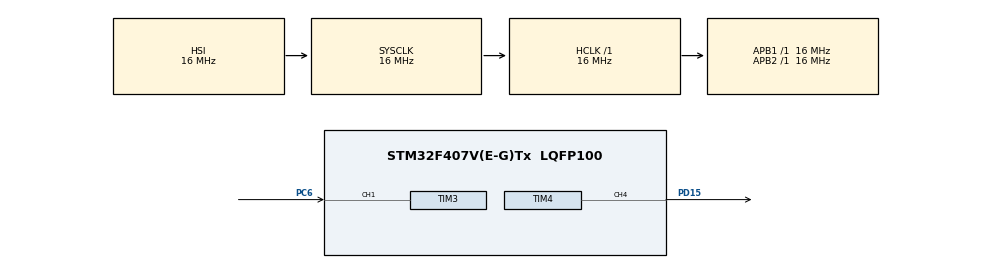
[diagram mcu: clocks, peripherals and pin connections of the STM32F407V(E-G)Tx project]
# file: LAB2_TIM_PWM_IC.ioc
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Dma.Request0=TIM3_CH1/TRIG
Dma.Request1=TIM3_CH2
Dma.TIM3_CH1/TRIG.0.Direction=DMA_PERIPH_TO_MEMORY
Dma.TIM3_CH1/TRIG.0.FIFOMode=DMA_FIFOMODE_DISABLE
Dma.TIM3_CH1/TRIG.0.Instance=DMA1_Stream4
Dma.TIM3_CH1/TRIG.0.MemDataAlignment=DMA_MDATAALIGN_HALFWORD
Dma.TIM3_CH1/TRIG.0.MemInc=DMA_MINC_ENABLE
Dma.TIM3_CH1/TRIG.0.Mode=DMA_CIRCULAR
Dma.TIM3_CH1/TRIG.0.PeriphDataAlignment=DMA_PDATAALIGN_HALFWORD
Dma.TIM3_CH1/TRIG.0.PeriphInc=DMA_PINC_DISABLE
Dma.TIM3_CH1/TRIG.0.Priority=DMA_PRIORITY_LOW
Dma.TIM3_CH2.1.Direction=DMA_PERIPH_TO_MEMORY
Dma.TIM3_CH2.1.FIFOMode=DMA_FIFOMODE_DISABLE
Dma.TIM3_CH2.1.Instance=DMA1_Stream5
Dma.TIM3_CH2.1.MemDataAlignment=DMA_MDATAALIGN_HALFWORD
Dma.TIM3_CH2.1.MemInc=DMA_MINC_ENABLE
Dma.TIM3_CH2.1.Mode=DMA_CIRCULAR
Dma.TIM3_CH2.1.PeriphDataAlignment=DMA_PDATAALIGN_HALFWORD
Dma.TIM3_CH2.1.PeriphInc=DMA_PINC_DISABLE
Dma.TIM3_CH2.1.Priority=DMA_PRIORITY_LOW
Mcu.Family=STM32F4
Mcu.Name=STM32F407V(E-G)Tx
Mcu.Package=LQFP100
NVIC.DMA1_Stream4_IRQn=true\:0\:0\:false\:false\:true\:false\:true\:true
NVIC.DMA1_Stream5_IRQn=true\:0\:0\:false\:false\:true\:false\:true\:true
NVIC.PriorityGroup=NVIC_PRIORITYGROUP_4
NVIC.TIM3_IRQn=true\:0\:0\:false\:false\:true\:true\:true\:true
PA13.Mode=Serial_Wire
PA13.Signal=SYS_JTMS-SWDIO
PA14.Mode=Serial_Wire
PA14.Signal=SYS_JTCK-SWCLK
PC6.Signal=S_TIM3_CH1
PD15.Signal=S_TIM4_CH4
ProjectManager.HeapSize=0x200
ProjectManager.StackSize=0x400
ProjectManager.TargetToolchain=MDK-ARM V5.32
RCC.AHBFreq_Value=16000000
RCC.APB1Freq_Value=16000000
RCC.APB2Freq_Value=16000000
RCC.CortexFreq_Value=16000000
RCC.HSE_VALUE=25000000
RCC.HSI_VALUE=16000000
RCC.LSE_VALUE=32768
RCC.SYSCLKFreq_VALUE=16000000
RCC.VCOOutputFreq_Value=192000000
SH.S_TIM3_CH1.0=TIM3_CH1,Input_Capture1_from_TI1
SH.S_TIM3_CH1.1=TIM3_CH1,TriggerSource_TI1FP1
SH.S_TIM4_CH4.0=TIM4_CH4,PWM Generation4 CH4
TIM3.Channel-Input_Capture1_from_TI1=TIM_CHANNEL_1
TIM3.Channel-Input_Capture2_from_TI1_63=TIM_CHANNEL_2
TIM3.ICPolarity_CH2=TIM_INPUTCHANNELPOLARITY_FALLING
TIM3.Prescaler=16-1
TIM3.TIM_MasterSlaveMode=TIM_MASTERSLAVEMODE_DISABLE
TIM4.Channel-PWM\ Generation4\ CH4=TIM_CHANNEL_4
TIM4.Period=2500-1
TIM4.Prescaler=16-1
TIM4.Pulse-PWM\ Generation4\ CH4=250
VP_TIM3_VS_ClockSourceINT.Mode=Internal
VP_TIM3_VS_ControllerModeReset.Mode=Reset Mode
VP_TIM3_VS_indirect_ch1.Mode=Input_Capture2_from_TI1_63
VP_TIM4_VS_ClockSourceINT.Mode=Internal
board=custom

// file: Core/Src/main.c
/* USER CODE BEGIN Header */
/**
  ******************************************************************************
  * @file           : main.c
  * @brief          : Main program body
  ******************************************************************************
  * @attention
  *
  * Copyright (c) 2023 STMicroelectronics.
  * All rights reserved.
  *
  * This software is licensed under terms that can be found in the LICENSE file
  * in the root directory of this software component.
  * If no LICENSE file comes with this software, it is provided AS-IS.
  *
  ******************************************************************************
  */
/* USER CODE END Header */
#include "main.h"
#include "dma.h"
#include "tim.h"
#include "gpio.h"

/* USER CODE BEGIN PV */
uint16_t t0 = 0;
uint16_t t1 = 0;
uint16_t t2 = 0;
uint16_t period = 0;
uint16_t pulse = 0;

#define BUFFER_SIZE 10
uint16_t buffer_ch1[BUFFER_SIZE] =  {0};
uint16_t buffer_ch2[BUFFER_SIZE] =  {0};
/* USER CODE END PV */

void SystemClock_Config(void);

int main(void)
{

  /* MCU Configuration--------------------------------------------------------*/

  /* Reset of all peripherals, Initializes the Flash interface and the Systick. */
  HAL_Init();

  /* Configure the system clock */
  SystemClock_Config();

  /* Initialize all configured peripherals */
  MX_GPIO_Init();
  MX_DMA_Init();
  MX_TIM3_Init();
  MX_TIM4_Init();
  /* USER CODE BEGIN 2 */
	HAL_TIM_Base_Start(&htim4);
	HAL_TIM_PWM_Start(&htim4, TIM_CHANNEL_4);

//	HAL_TIM_IC_Start_IT(&htim3, TIM_CHANNEL_1);
//	HAL_TIM_IC_Start_IT(&htim3, TIM_CHANNEL_2);
	HAL_TIM_IC_Start_DMA(&htim3, TIM_CHANNEL_1, (uint32_t *)buffer_ch1, BUFFER_SIZE);
	HAL_TIM_IC_Start_DMA(&htim3, TIM_CHANNEL_2, (uint32_t *)buffer_ch2, BUFFER_SIZE);
	HAL_TIM_Base_Start(&htim3);
  /* USER CODE END 2 */

  /* Infinite loop */
  /* USER CODE BEGIN WHILE */
  while (1)
  {
		uint32_t temp_period = 0;
		uint32_t temp_pulse = 0;
		for (uint8_t i = 0; i < BUFFER_SIZE; i++)
		{
			temp_period += buffer_ch1[i];
			temp_pulse += buffer_ch2[i];
		}
		period = temp_period / BUFFER_SIZE;
		pulse = temp_pulse / BUFFER_SIZE;
    /* USER CODE END WHILE */

  }
}

void SystemClock_Config(void)
{
  RCC_OscInitTypeDef RCC_OscInitStruct = {0};
  RCC_ClkInitTypeDef RCC_ClkInitStruct = {0};

  /** Configure the main internal regulator output voltage
  */
  __HAL_RCC_PWR_CLK_ENABLE();
  __HAL_PWR_VOLTAGESCALING_CONFIG(PWR_REGULATOR_VOLTAGE_SCALE1);

  /** Initializes the RCC Oscillators according to the specified parameters
  * in the RCC_OscInitTypeDef structure.
  */
  RCC_OscInitStruct.OscillatorType = RCC_OSCILLATORTYPE_HSI;
  RCC_OscInitStruct.HSIState = RCC_HSI_ON;
  RCC_OscInitStruct.HSICalibrationValue = RCC_HSICALIBRATION_DEFAULT;
  RCC_OscInitStruct.PLL.PLLState = RCC_PLL_NONE;
  if (HAL_RCC_OscConfig(&RCC_OscInitStruct) != HAL_OK)
  {
    Error_Handler();
  }

  /** Initializes the CPU, AHB and APB buses clocks
  */
  RCC_ClkInitStruct.ClockType = RCC_CLOCKTYPE_HCLK|RCC_CLOCKTYPE_SYSCLK
                              |RCC_CLOCKTYPE_PCLK1|RCC_CLOCKTYPE_PCLK2;
  RCC_ClkInitStruct.SYSCLKSource = RCC_SYSCLKSOURCE_HSI;
  RCC_ClkInitStruct.AHBCLKDivider = RCC_SYSCLK_DIV1;
  RCC_ClkInitStruct.APB1CLKDivider = RCC_HCLK_DIV1;
  RCC_ClkInitStruct.APB2CLKDivider = RCC_HCLK_DIV1;

  if (HAL_RCC_ClockConfig(&RCC_ClkInitStruct, FLASH_LATENCY_0) != HAL_OK)
  {
    Error_Handler();
  }
}

/* USER CODE BEGIN 4 */

void HAL_TIM_IC_CaptureCallback(TIM_HandleTypeDef *htim)
{
	if (htim->Channel == HAL_TIM_ACTIVE_CHANNEL_1)
	{
		t0 = t2;
		t2 = __HAL_TIM_GET_COMPARE(&htim3, TIM_CHANNEL_1);
		period = t2 - t0;
		pulse = t1 - t0;
	}
	if (htim->Channel == HAL_TIM_ACTIVE_CHANNEL_2)
	{
		t1 = __HAL_TIM_GET_COMPARE(&htim3, TIM_CHANNEL_2);
	}
}
/* USER CODE END 4 */

void Error_Handler(void)
{
  __disable_irq();
  while (1)
  {
  }
}
